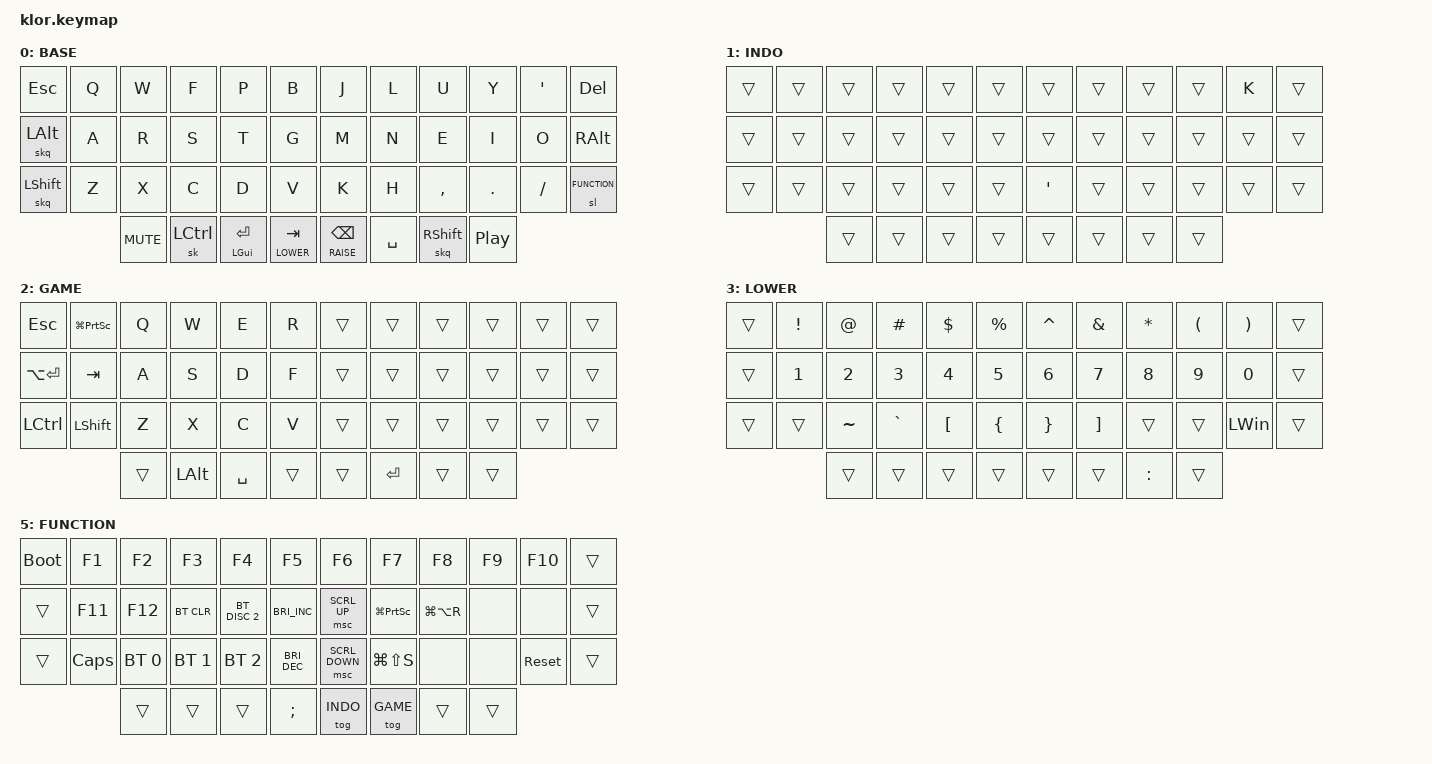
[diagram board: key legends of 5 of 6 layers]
//                               █         █    █            ▄▄▄▀▀▀▀▀▀▄▄▄        █▀▀▀▀▀▀▀▀▀▀█
//                               █        █     █          ▄▀            ▀▄      █          █
//                               █       █      █        ▄▀                ▀▄    █          █
//                               █      █       █        █                  █    █          █
//                               █     █        █       █                    █   █          █
//                               █    █         █       █                    █   █▄▄▄▄▄▄▄▄▄▄█
//                               █   █ █        █       █                    █   █      █
//                               █  █   █       █        █                  █    █       █
//                               █ █     █      █        ▀▄                ▄▀    █        █
//                               ██       █     █          ▀▄            ▄▀      █         █
//                               █         █    █▄▄▄▄▄▄▄▄    ▀▀▀▄▄▄▄▄▄▀▀▀        █          █
//
// ▄▄▄▄▄▄▄▄▄▄▄▄▄▄▄▄▄▄▄▄▄▄▄▄▄▄▄▄▄▄▄▄▄▄▄▄▄▄▄▄▄▄▄▄▄▄▄▄▄▄▄▄▄▄▄▄▄▄▄▄▄▄▄▄▄▄▄▄▄▄▄▄▄▄▄▄▄▄▄▄▄▄▄▄▄▄▄▄▄▄▄▄▄▄▄▄▄▄▄▄▄▄▄▄▄▄▄▄▄▄▄▄▄▄▄▄▄▄▄▄▄▄▄▄▄

#include <behaviors.dtsi>
#include <dt-bindings/zmk/bt.h>
#include <dt-bindings/zmk/keys.h>

#define ZMK_POINTING_DEFAULT_SCRL_VAL 50

#include <dt-bindings/zmk/pointing.h>

#define BASE     0
#define INDO     1
#define GAME     2
#define LOWER    3
#define RAISE    4
#define FUNCTION 5

&msc {
    time-to-max-speed-ms = <50>;
    acceleration-exponent = <1>;
};

&sl {
    release-after-ms = <1000>;
};

/ {
    behaviors {
        hm: homerow_mods {
            compatible = "zmk,behavior-hold-tap";
            label = "HOMEROW_MODS";
            #binding-cells = <2>;
            tapping-term-ms = <150>;
            quick_tap_ms = <0>;
            flavor = "tap-preferred";
            bindings = <&kp>, <&kp>;
        };

        skq: sticky_key_quick_release {
            compatible = "zmk,behavior-sticky-key";
            label = "SK_QUICK_RELEASE";
            #binding-cells = <1>;
            bindings = <&kp>;
            release-after-ms = <500>;
            quick-release;
            ignore-modifiers;
        };
        
        sensor_rotate_msc: sensor_rotate_msc {
            compatible = "zmk,behavior-sensor-rotate-var";
            #sensor-binding-cells = <2>;
            bindings = <&msc>, <&msc>;
            tap-ms = <50>;
        };

        sensor_rotate_trans: sensor_rotate_trans {
            compatible = "zmk,behavior-sensor-rotate-var";
            #sensor-binding-cells = <2>;
            bindings = <&trans>, <&trans>;
            tap-ms = <50>;
        };
    };

    combos {
        compatible = "zmk,combos";

        combo_esc {
            timeout-ms = <50>;
            key-positions = <1 2>;
            bindings = <&kp ESC>;
        };

        double_shift {
            bindings = <&caps_word>;
            key-positions = <24 42>;
        };

        combo_m_you {
            bindings = <&m_you>;
            key-positions = <8 9>;
            layers = <0>;
            timeout-ms = <40>;
        };

        combo_m_eye {
            bindings = <&m_eye>;
            key-positions = <20 9>;
            timeout-ms = <50>;
            layers = <0>;
        };

        combo_undo {
            bindings = <&kp LC(Z)>;
            key-positions = <25 26>;
            timeout-ms = <50>;
        };

        combo_cut {
            bindings = <&kp LC(X)>;
            key-positions = <26 27>;
            timeout-ms = <50>;
        };

        combo_copy {
            bindings = <&kp LC(C)>;
            key-positions = <27 28>;
            timeout-ms = <50>;
        };

        combo_paste {
            bindings = <&kp LC(V)>;
            key-positions = <28 29>;
            timeout-ms = <50>;
        };

        combo_under {
            bindings = <&kp UNDER>;
            key-positions = <30 31>;
            timeout-ms = <50>;
        };

        combo_dash {
            bindings = <&kp MINUS>;
            key-positions = <31 32>;
            timeout-ms = <50>;
        };
    };

    macros {
        m_you: m_you {
            compatible = "zmk,behavior-macro";
            #binding-cells = <0>;
            bindings = <&kp Y &kp O &kp U>;
            label = "M_YOU";
        };

        m_eye: m_eye {
            compatible = "zmk,behavior-macro";
            #binding-cells = <0>;
            bindings = <&kp E &kp Y &kp E>;
            label = "M_EYE";
        };
    };

    keymap {
        compatible = "zmk,keymap";

        base_layer {
            label = "BASE";
            bindings = <
&kp ESCAPE  &kp Q  &kp W       &kp F      &kp P         &kp B          &kp J           &kp L      &kp U       &kp Y             &kp SINGLE_QUOTE  &kp DELETE  
&skq LALT   &kp A  &kp R       &kp S      &kp T         &kp G          &kp M           &kp N      &kp E       &kp I             &kp O             &kp RIGHT_ALT  
&skq LSHFT  &kp Z  &kp X       &kp C      &kp D         &kp V          &kp K           &kp H      &kp COMMA   &kp DOT           &kp FSLH          &sl FUNCTION
                   &kp C_MUTE  &sk LCTRL  &mt LGUI RET  &lt LOWER TAB  &lt RAISE BSPC  &kp SPACE  &skq RSHFT  &kp C_PLAY_PAUSE
            >;

            sensor-bindings = <&inc_dec_kp C_VOL_UP C_VOL_DN &sensor_rotate_msc SCRL_UP SCRL_DOWN>;
        };

        indo_layer {
            label = "INDO";
            bindings = <
&trans  &trans  &trans  &trans  &trans  &trans  &trans    &trans  &trans  &trans  &kp K   &trans
&trans  &trans  &trans  &trans  &trans  &trans  &trans    &trans  &trans  &trans  &trans  &trans
&trans  &trans  &trans  &trans  &trans  &trans  &kp APOS  &trans  &trans  &trans  &trans  &trans
                &trans  &trans  &trans  &trans  &trans    &trans  &trans  &trans
            >;

            sensor-bindings = <&inc_dec_kp C_VOL_UP C_VOL_DN &sensor_rotate_msc SCRL_UP SCRL_DOWN>;
        };
        
        game_layer {
            label = "GAME";
            bindings = <
&kp ESCAPE     &kp LG(PSCRN)  &kp Q   &kp W   &kp E     &kp R      &trans  &trans  &trans   &trans  &trans  &trans  
&kp LA(ENTER)  &kp TAB        &kp A   &kp S   &kp D     &kp F      &trans  &trans  &trans   &trans  &trans  &trans  
&kp LCTRL      &kp LSHFT      &kp Z   &kp X   &kp C     &kp V      &trans  &trans  &trans   &trans  &trans  
                              &trans  &trans  &kp LALT  &kp SPACE  &trans  &trans  &kp RET  &trans  &trans
            >;

            sensor-bindings = <&inc_dec_kp C_VOL_UP C_VOL_DN &sensor_rotate_msc SCRL_UP SCRL_DOWN>;
        };

        lower_layer {
            label = "LOWER";
            bindings = <
&trans  &kp EXCLAMATION  &kp AT_SIGN   &kp HASH      &kp DOLLAR        &kp PERCENT     &kp CARET        &kp AMPERSAND      &kp ASTERISK    &kp LEFT_PARENTHESIS  &kp RIGHT_PARENTHESIS  &trans
&trans  &kp NUMBER_1     &kp NUMBER_2  &kp NUMBER_3  &kp NUMBER_4      &kp NUMBER_5    &kp NUMBER_6     &kp NUMBER_7       &kp NUMBER_8    &kp NUMBER_9          &kp NUMBER_0           &trans  
&trans  &trans           &kp TILDE     &kp GRAVE     &kp LEFT_BRACKET  &kp LEFT_BRACE  &kp RIGHT_BRACE  &kp RIGHT_BRACKET  &trans          &trans                &kp LEFT_WIN           &trans  
                         &trans        &trans        &trans            &trans          &trans           &trans             &kp COLON       &trans
            >;

            sensor-bindings = <&inc_dec_kp C_FAST_FORWARD C_REWIND &inc_dec_kp PG_DN PG_UP>;
        };

        raise_layer {
            label = "RAISE";
            bindings = <
&trans  &kp DELETE  &trans   &kp UNDER      &kp PLUS       &kp PAGE_UP    &trans            &trans      &trans      &kp BSLH           &kp PIPE         &trans
&trans  &kp HOME    &kp END  &kp MINUS      &kp EQUAL      &kp PAGE_DOWN  &kp LEFT          &kp DOWN    &kp UP      &kp RIGHT          &kp K_APP        &trans
&trans  &kp LT      &kp GT   &kp LC(LS(C))  &kp LC(LS(V))  &kp SEMI       &kp C_PLAY_PAUSE  &kp C_PREV  &kp C_NEXT  &kp C_VOLUME_DOWN  &kp C_VOLUME_UP  &trans
                    &trans   &kp ESCAPE     &trans         &kp SEMICOLON  &trans            &kp MINUS   &trans      &trans             &trans
            >;

            sensor-bindings = <&inc_dec_kp RIGHT LEFT &sensor_rotate_msc LC(PLUS) LC(MINUS)>;
        };

        function_layer {
            label = "FUNCTION";
            bindings = <
&bootloader  &kp F1    &kp F2        &kp F3        &kp F4         &kp F5                &kp F6          &kp F7         &kp F8         &kp F9  &kp F10     &trans  
&trans       &kp F11   &kp F12       &bt BT_CLR    &bt BT_DISC 2  &kp C_BRIGHTNESS_INC  &msc SCRL_UP    &kp LG(PSCRN)  &kp LG(LA(R))  &none   &none       &trans
&trans       &kp CAPS  &bt BT_SEL 0  &bt BT_SEL 1  &bt BT_SEL 2   &kp C_BRIGHTNESS_DEC  &msc SCRL_DOWN  &kp LG(LS(S))  &none          &none   &sys_reset  &trans  
                       &trans        &trans        &trans         &kp SEMICOLON         &tog INDO       &tog GAME      &trans         &trans
            >;

            sensor-bindings = <&inc_dec_kp C_BRI_INC C_BRI_DEC &inc_dec_kp LC(Y) LC(Z)>;
        };

        extra1 { status = "reserved"; };

        extra2 { status = "reserved"; };
    };
};
